# afe_adc_one_reva register map
Registers are 16-bit, access not given, no defined reset value unless marked. A register's access mark holds for its fields unless they carry their own. Offsets are from the block's base; lines under a group give offsets from that group; [hi:lo] are bit positions; {n}, {i} and the like mark numbered series; 'fields as' and 'values as' point back to an identical list; <NAME> marks a mode.

## Memory map
0x4FA00000 AFE_ADC_ONE size 0x200 — Analog Front End ADC1 on Stacked Die via SPI

## AFE_ADC_ONE — Analog Front End ADC1 on Stacked Die via SPI
Base 0x4FA00000
0x800001 PD 8-bit — Power down
  [1:0] PD — Description not included
    0=Normal_Mode (Description not included); 1=Standby_Mode (Description not included); 2=Sleep_Mode (Description not included); 3=Reset (Description not included)
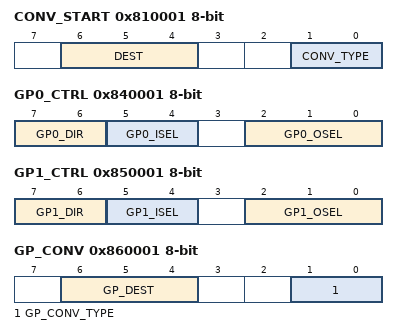
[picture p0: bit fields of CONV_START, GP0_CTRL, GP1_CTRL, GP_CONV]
0x810001 CONV_START 8-bit — Initiate conversions
  [6:4] DEST — Description not included
  [1:0] CONV_TYPE — Description not included
    0=SINGLE (Description not included); 1=CONTINUOUS (Description not included); 2=DUTY_CYCLED_1_TO_4 (Description not included)
0x820001 SEQ_START 8-bit — Execute a sequence at written address (0x3A to 0x6E)
  [7:0] SEQ_ADDRESS — Description not included
0x830001 CAL_START 8-bit — Execute selected calibration
  [2:0] CAL_TYPE — Description not included
0x840001 GP0_CTRL 8-bit — Control behavior of GPIO0
  [7:6] GP0_DIR — Description not included
  [5:4] GP0_ISEL — Description not included
  [2:0] GP0_OSEL — Description not included
0x850001 GP1_CTRL 8-bit — Control behavior of GPIO1
  [7:6] GP1_DIR — Description not included
  [5:4] GP1_ISEL — Description not included
  [2:0] GP1_OSEL — Description not included
0x860001 GP_CONV 8-bit — Select conversion to perform when initiated by GPIO
  [6:4] GP_DEST — Description not included
  [1:0] GP_CONV_TYPE — Description not included
    values as CONV_START.CONV_TYPE
0x870001 GP_SEQ_ADDR 8-bit — Select target sequencer address initiated by GPIO
  [6:0] GP_SEQ_ADDR — Description not included
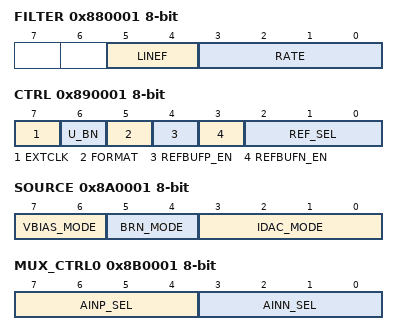
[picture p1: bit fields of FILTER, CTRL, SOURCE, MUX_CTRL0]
0x880001 FILTER 8-bit — Select conversion data rate and filter behavior
  [5:4] LINEF — Description not included
    0=SIMULTANEOUS_FIR_REJECT_50HZ_AND_60HZ (Description not included); 1=FIR_REJECT_50HZ (Description not included); 2=FIR_REJECT_60HZ (Description not included); 3=SINC4 (Description not included)
  [3:0] RATE — Description not included
0x890001 CTRL 8-bit — Select clock source, data format, ref inputs and ref buffers
  [7] EXTCLK — Description not included
  [6] U_BN — Description not included
  [5] FORMAT — Description not included
  [4] REFBUFP_EN — Description not included
  [3] REFBUFN_EN — Description not included
  [2:0] REF_SEL — Description not included
    0=REF0P_AND_REF0N (Description not included); 1=REF1P_AND_REF1N (Description not included); 2=REF2P_AND_REF2N (Description not included); 3=AVDD_AND_AGND (Description not included); 4=REF0P_AND_AGND (Description not included); 5=REF1P_AND_AGND (Description not included); 6=REF2P_AND_AGND (Description not included)
0x8A0001 SOURCE 8-bit — Configures excitation current, burnout current, and bias voltage sources.
  [7:6] VBIAS_MODE — Description not included
    0=ACTIVE_MODE (Description not included); 1=OUTPUT_IMPEDANCE_125K_OHM (Description not included); 2=OUTPUT_IMPEDANCE_20K_OHM (Description not included)
  [5:4] BRN_MODE — Description not included
    0=POW_DOWN_CUR_SRC_DISABLED (Description not included); 1=CUR_SRC_0_5UA (Description not included); 2=CUR_SRC_1UA (Description not included); 3=CUR_SRC_10_UA (Description not included)
  [3:0] IDAC_MODE — Description not included
    0=CUR_10UA (Description not included); 1=CUR_50UA (Description not included); 2=CUR_75UA (Description not included); 3=CUR_100UA (Description not included); 4=CUR_125UA (Description not included); 5=CUR_150UA (Description not included); 6=CUR_175UA (Description not included); 7=CUR_200UA (Description not included); 8=cur_225UA (description not included); 9=cur_250UA (description not included); 10=CUR_300UA (Description not included); 11=CUR_400UA (Description not included); 12=CUR_600UA (Description not included); 13=cur_800UA (description not included); 14=CUR_1200UA (Description not included); 15=CUR_1600UA (Description not included)
0x8B0001 MUX_CTRL0 8-bit — Selects analog inputs for AINP and AINN
  [7:4] AINP_SEL — Description not included
  [3:0] AINN_SEL — Description not included
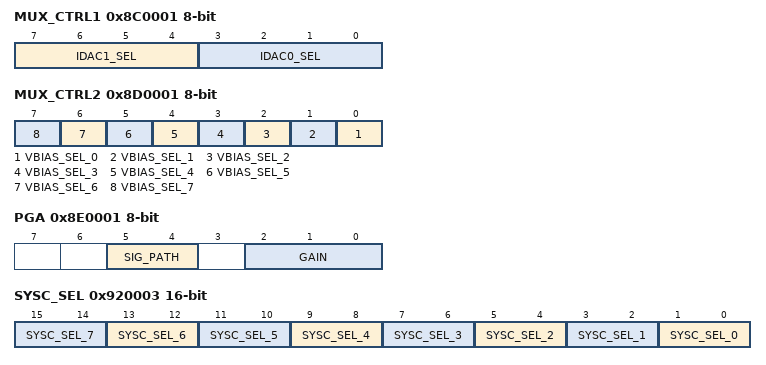
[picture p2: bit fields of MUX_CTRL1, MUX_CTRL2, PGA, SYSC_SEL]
0x8C0001 MUX_CTRL1 8-bit — Selects excitation current sources and which input they are connected to
  [7:4] IDAC1_SEL — Description not included
  [3:0] IDAC0_SEL — Description not included
0x8D0001 MUX_CTRL2 8-bit — Connection of VBIAS source to input mux
  [n] VBIAS_SEL_{n} (n=0..7) — Description not included
0x8E0001 PGA 8-bit — Signal path control of input buffers and PGA
  [5:4] SIG_PATH — Description not included
    0=BUFFERED_UNITY_GAIN_PATH (Description not included); 1=BYPASS_PATH (Description not included); 2=PGA_PATH (Description not included); 3=RESERVED (Description not included)
  [2:0] GAIN — Description not included
    0=GAIN_1X (Description not included); 1=GAIN_2X (Description not included); 2=GAIN_4X (Description not included); 3=GAIN_8X (Description not included); 4=GAIN_16X (Description not included); 5=GAIN_32X (Description not included); 6=GAIN_64X (Description not included); 7=GAIN_128X (Description not included)
0x8F0001 WAIT_EXT 8-bit — Extends count range of WAIT command
  [7:0] WAIT_EXT — Description not included
0x900001 WAIT_START 8-bit — Executes wait operation
0x910003 PART_ID size not given ro — Silicon Revision ID
  [2:0] REV_ID — Description not included
0x920003 SYSC_SEL size not given — System Calibration Selection
  [2n+1:2n] SYSC_SEL_{n} (n=0..7) — Description not included
0x930003 SYS_OFF_A size not given — System offset A calibration value to subtract from conversion results
  [23:0] SYS_OFF_A — Description not included
0x940003 SYS_OFF_B size not given — System offset B calibration value to subtract from conversion results
  [23:0] SYS_OFF_B — Description not included
0x950003 SYS_GAIN_A size not given — System gain calibration A value to scale offset corrected conversion results
  [23:0] SYS_GAIN_A — Description not included
0x960003 SYS_GAIN_B size not given — System gain calibration B value to scale offset corrected conversion results
  [23:0] SYS_GAIN_B — Description not included
0x970003 SELF_OFF size not given — Self-calibration offset value to subtract from conversion results
  [23:0] SELF_OFF — Description not included
0x980003 SELF_GAIN_1 size not given — Self-calibration gain value to scale offset corrected conversion results for gain 1
  [23:0] SELF_GAIN_1 — Description not included
0x990003 SELF_GAIN_2 size not given — Self-calibration gain value to scale offset corrected conversion results for gain 2
  [23:0] SELF_GAIN_1 — Description not included
0x9A0003 SELF_GAIN_4 size not given — Self-calibration gain value to scale offset corrected conversion results for gain 4
  [23:0] SELF_GAIN_4 — Description not included
0x9B0003 SELF_GAIN_8 size not given — Self-calibration gain value to scale offset corrected conversion results for gain 8
  [23:0] SELF_GAIN_8 — Description not included
0x9C0003 SELF_GAIN_16 size not given — Self-calibration gain value to scale offset corrected conversion results for gain 16
  [23:0] SELF_GAIN_16 — Description not included
0x9D0003 SELF_GAIN_32 size not given — Self-calibration gain value to scale offset corrected conversion results for gain 32
  [23:0] SELF_GAIN_32 — Description not included
0x9E0003 SELF_GAIN_64 size not given — Self-calibration gain value to scale offset corrected conversion results for gain 64
  [23:0] SELF_GAIN_64 — Description not included
0x9F0003 SELF_GAIN_128 size not given — Self-calibration gain value to scale offset corrected conversion results for gain 128
  [23:0] LTHRESH0 — Description not included
{0xA00003+0x10000*i} LTHRESH{i} size not given (i=0..7) — Lower comparison threshold for DATA registers
  [23:0] LTHRESH — Description not included
{0xA80003+0x10000*i} UTHRESH{i} size not given (i=0..7) — Upper comparison threshold for DATA registers
  [23:0] UTHRESH — Description not included
{0xB00003+0x10000*i} DATA{i} size not given (i=0..7) — ADC conversion result storage
  [23:0] DATA{i} — Description not included
0xB80003 STATUS size not given — Device Status, INTB source etc.
  [n+16] TOR_{n} (n=0..7) — Description not included
  [n+8] TUR_{n} (n=0..7) — Description not included
  [7] SYSGOR — Description not included
  [4] DATA_RDY — Description not included
  [3] WAIT_DONE — Description not included
  [2] CAL_RDY — Description not included
  [1] SEQ_RDY — Description not included
  [0] CONV_RDY — Description not included
0xB90003 STATUS_IE size not given — Device Status, INTB source etc. Enable Register
  [n+16] TOR_IE_{n} (n=0..7) — Description not included
  [n+8] TUR_IE_{n} (n=0..7) — Description not included
  [7] SYSGOR_IE — Description not included
  [4] DATA_RDY_IE — Description not included
  [3] WAIT_DONE_IE — Description not included
  [2] CAL_RDY_IE — Description not included
  [1] SEQ_RDY_IE — Description not included
  [0] CONV_RDY_IE — Description not included
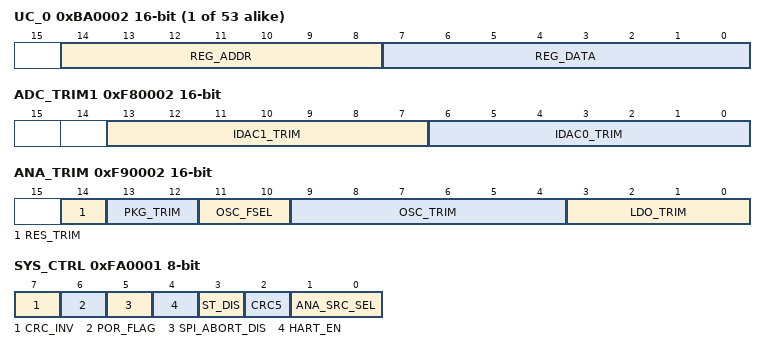
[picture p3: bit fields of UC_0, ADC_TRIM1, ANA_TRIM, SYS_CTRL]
{0xBA0002+0x10000*i} UC_{i} (i=0..52) — Sequencer Register
  [14:8] REG_ADDR — Description not included
  [7:0] REG_DATA — Description not included
0xEF0001 UCADDR 8-bit — Address of currently executing sequence command
  [6:0] UCADDR — Description not included
0xF00001 FT_PWORD 8-bit — FT Password
  [6:0] FT_PWORD — Description not included
    72=PWORD_1 (Description not included); 123=PWORD_2 (Description not included)
0xF70003 ADC_TRIM0 size not given — Various ADC Analog Trims
  [18:17] CLKSKEW — Description not included
  [16:11] IB_TRIM — Description not included
  [10:6] IP_TRIM — Description not included
  [5:0] VGB_TRIM — Description not included
0xF80002 ADC_TRIM1 — Various ADC Analog Trims
  [13:7] IDAC1_TRIM — Description not included
  [6:0] IDAC0_TRIM — Description not included
0xF90002 ANA_TRIM — Various Analog Trims
  [14] RES_TRIM — Description not included
  [13:12] PKG_TRIM — Description not included
  [11:10] OSC_FSEL — Description not included
  [9:4] OSC_TRIM — Description not included
  [3:0] LDO_TRIM — Description not included
0xFA0001 SYS_CTRL 8-bit — System Calibration Selection
  [7] CRC_INV — Description not included
  [6] POR_FLAG — Description not included
  [5] SPI_ABORT_DIS — Description not included
  [4] HART_EN — Description not included
  [3] ST_DIS — Description not included
  [2] CRC5 — Description not included
  [1:0] ANA_SRC_SEL — Description not included
    0=ADC0_BANK (Description not included); 1=ADC1_BANK (Description not included); 2=DAC12_BANK (Description not included); 3=HART_BANK (Description not included)
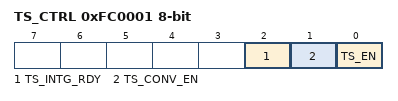
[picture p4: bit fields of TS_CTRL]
0xFC0001 TS_CTRL 8-bit — Temperature Sensor Control
  [2] TS_INTG_RDY — Description not included
  [1] TS_CONV_EN — Description not included
  [0] TS_EN — Description not included
